# MSPM0G321X register map
Vendor: Texas Instruments; File version: Revised: 2025-10-06 10:58:04
CPU: CM0 r0p1, little endian, MPU, no FPU, 3 interrupt priority bits
Registers are 32-bit, read-write, reset 0x0 unless marked. A register's access mark holds for its fields unless they carry their own. Offsets are from the block's base; [hi:lo] are bit positions; lines under a group give offsets from that group; {n}, {i} and the like mark numbered series; 'fields as' and 'values as' point back to an identical list.

## TIMB0 — PERIPHERALREGION
Base 0x400B8000
0x400 TIMB0_FSUB_0 — Subscriber Configuration Register.
  [3:0] CHANID — 0 = disconnected. 1-15 = connected to channelID = CHANID.
    0=UNCONNECTED (A value of 0 specifies that the event is not connected)
0x444 TIMB0_FPUB_0 — Publisher Port 0
  fields as TIMB0_FSUB_0
{0x800+0x18*i} TIMB0_GPRCM[{i}] (i=0..0) group
  0x00 TIMB0_PWREN — Power enable
    [0] ENABLE — Enable the power
      0=DISABLE (Disable Power); 1=ENABLE (Enable Power)
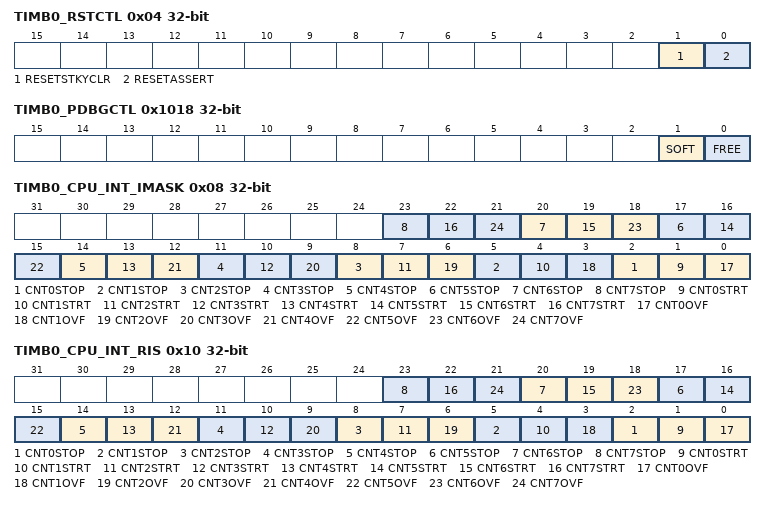
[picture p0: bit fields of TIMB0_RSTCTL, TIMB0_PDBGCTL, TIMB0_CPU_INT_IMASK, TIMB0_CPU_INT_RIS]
  0x04 TIMB0_RSTCTL wo — Reset Control
    [1] RESETSTKYCLR — Clear the RESETSTKY bit in the STAT register
      0=NOP (Writing 0 has no effect); 1=CLR (Clear reset sticky bit)
    [0] RESETASSERT — Assert reset to the peripheral
      0=NOP (Writing 0 has no effect); 1=ASSERT (Assert reset)
  0x14 TIMB0_STAT ro — Status Register
    [16] RESETSTKY — This bit indicates, if the peripheral was reset, since this bit was cleared by RESETSTKYCLR in the RSTCTL register
      0=NORES (The peripheral has not been reset since this bit was last cleared by RESETSTKYCLR in the RSTCTL register); 1=RESET (The peripheral was reset since the last bit clear)
0x1018 TIMB0_PDBGCTL — Peripheral Debug Control
  [1] SOFT — Soft halt boundary control. This function is only available, if [FREE] is set to 'STOP'
    0=IMMEDIATE (The peripheral will halt immediately, even if the resultant state will result in corruption if the system is restarted); 1=DELAYED (The peripheral blocks the debug freeze until it has reached a boundary where it can resume without corruption)
  [0] FREE — Free run control
    0=STOP (The peripheral freezes functionality while the Core Halted input is asserted and resumes when it is deasserted.); 1=RUN (The peripheral ignores the state of the Core Halted input)
{0x1020+0x2C*i} TIMB0_CPU_INT[{i}] (i=0..0) group
  0x00 TIMB0_CPU_INT_IIDX ro — Interrupt index
    [9:0] STAT — Interrupt index status
      0=NO_INTR (No bit is set means there is no pending interrupt request); 1=CNT0OVF (Counter0 period match interrupt); 2=CNT0STRT (Counter 0 start); 3=CNT0STOP (Counter0 stop); 4=CNT1OVF (Counter1 period match interrupt); 5=CNT1STRT (Counter 1 start); 6=CNT1STOP (Counter1 stop); 7=CNT2OVF (Counter2 period match interrupt); 8=CNT2STRT (Counter 2 start); 9=CNT2STOP (Counter2 stop); 10=CNT3OVF (Counter3 period match interrupt); 11=CNT3STRT (Counter 3 start); 12=CNT3STOP (Counter3 stop); 13=CNT4OVF (Counter4 period match interrupt); 14=CNT4STRT (Counter 4 start); 15=CNT4STOP (Counter4 stop); 16=CNT5OVF (Counter5 period match interrupt); 17=CNT5STRT (Counter 5 start); 18=CNT5STOP (Counter5 stop); 19=CNT6OVF (Counter6 period match interrupt); 20=CNT6STRT (Counter 6 start); 21=CNT6STOP (Counter6 stop); 22=CNT7OVF (Counter7 period match interrupt); 23=CNT7STRT (Counter 7 start); 24=CNT7STOP (Counter7 stop)
  0x08 TIMB0_CPU_INT_IMASK — Interrupt Mask. If a bit is set, then corresponding interrupt is un-masked. Un-masking the interrupt causes the raw interrupt to be visible in IIDX, as well as MIS.
    [all] fields
      0=CLR (Interrupt is not pending.); 1=SET (Interrupt is pending.)
    [3n+2] CNT{n}STOP (n=0..7) — CNT{n}STOP Interrupt enable bit
    [3n+1] CNT{n}STRT (n=0..7) — CNT{n}STRT Interrupt enable bit
    [3n] CNT{n}OVF (n=0..7) — CNT{n}OVF Interrupt enable bit
  0x10 TIMB0_CPU_INT_RIS ro — Raw interrupt status. Reflects all pending interrupts, regardless of masking. The RIS register allows the user to implement a poll scheme. A flag set in this register can be cleared by writing 1 to the ICLR register bit even if the corresponding IMASK bit is not enabled.
    [all] fields
      values as the fields of TIMB0_CPU_INT[0].TIMB0_CPU_INT_IMASK
    [3n+2] CNT{n}STOP (n=0..7) — Counter {n} stop event flag
    [3n+1] CNT{n}STRT (n=0..7) — Counter {n} start event flag
    [3n] CNT{n}OVF (n=0..7) — Counter {n} Period match flag
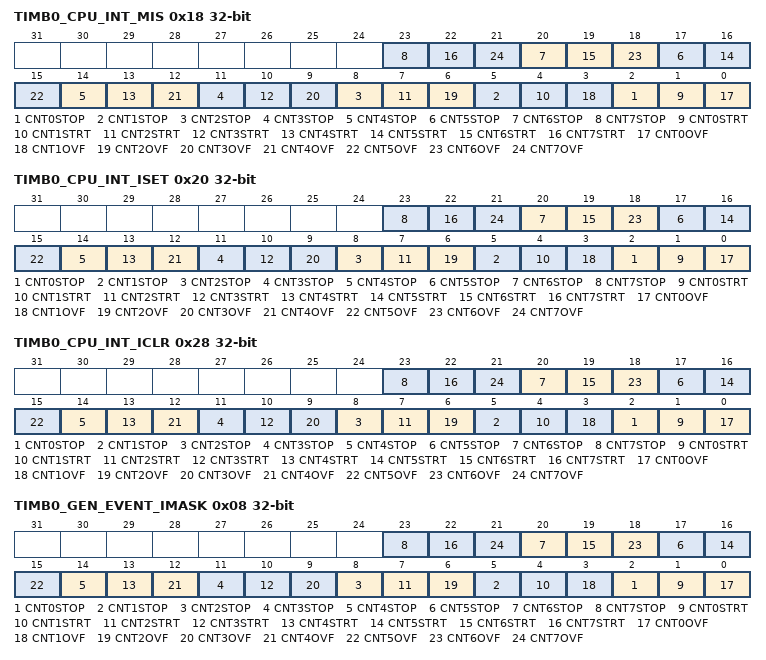
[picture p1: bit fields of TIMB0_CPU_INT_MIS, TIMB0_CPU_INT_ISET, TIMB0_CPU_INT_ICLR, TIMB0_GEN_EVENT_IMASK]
  0x18 TIMB0_CPU_INT_MIS ro — Masked interrupt status. This is an AND of the IMASK and RIS registers.
    [all] fields
      values as the fields of TIMB0_CPU_INT[0].TIMB0_CPU_INT_IMASK
    [3n+2] CNT{n}STOP (n=0..7) — Counter {n} stop event flag.
    [3n+1] CNT{n}STRT (n=0..7) — Counter {n} start event flag.
    [3n] CNT{n}OVF (n=0..7) — Counter {n} period match flag.
  0x20 TIMB0_CPU_INT_ISET wo — Interrupt set. Allows interrupts to be set by software (useful in diagnostics and safety checks). Writing a 1 to a bit in ISET will set the event and therefore the related RIS bit also gets set. If the interrupt is enabled through the mask, then the corresponding MIS bit is also set.
    [all] fields
      0=NO_EFFECT (Interrupt is not pending.); 1=SET (Interrupt is pending.)
    [3n+2] CNT{n}STOP (n=0..7) — Set Counter {n} stop event flag
    [3n+1] CNT{n}STRT (n=0..7) — Set Counter {n} start event flag
    [3n] CNT{n}OVF (n=0..7) — Set Counter {n} period match flag
  0x28 TIMB0_CPU_INT_ICLR wo — Interrupt clear. Write a 1 to clear corresponding Interrupt.
    [all] fields
      0=NO_EFFECT (Interrupt is not pending.); 1=CLR (Interrupt is pending.)
    [3n+2] CNT{n}STOP (n=0..7) — Clear Counter {n} stop event flag.
    [3n+1] CNT{n}STRT (n=0..7) — Clear Counter {n} start event flag.
    [3n] CNT{n}OVF (n=0..7) — Clear Counter {n} period match flag.
{0x1050+0x2C*i} TIMB0_GEN_EVENT[{i}] (i=0..0) group
  0x00 TIMB0_GEN_EVENT_IIDX ro — Interrupt index
    fields as TIMB0_CPU_INT[0].TIMB0_CPU_INT_IIDX
  0x08 TIMB0_GEN_EVENT_IMASK — Interrupt Mask. If a bit is set, then corresponding interrupt is un-masked. Un-masking the interrupt causes the raw interrupt to be visible in IIDX, as well as MIS.
    fields as TIMB0_CPU_INT[0].TIMB0_CPU_INT_IMASK
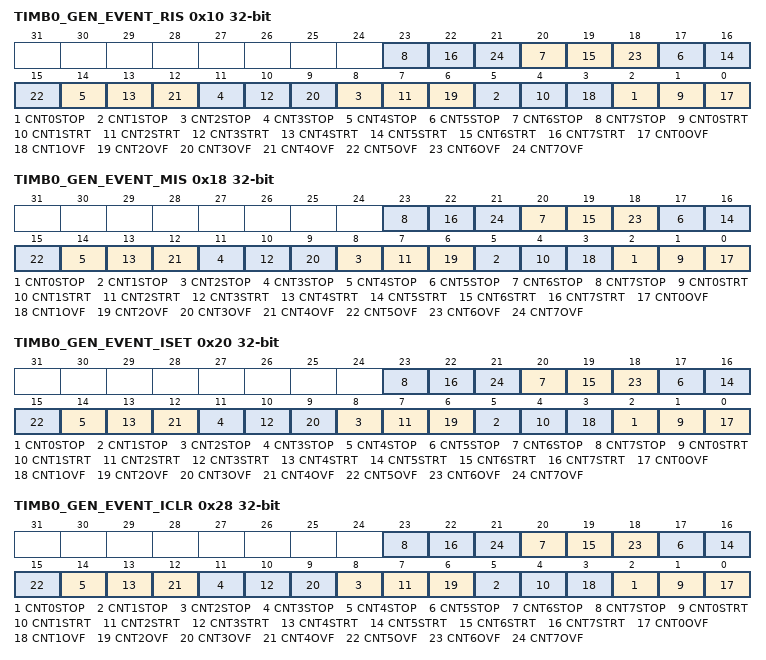
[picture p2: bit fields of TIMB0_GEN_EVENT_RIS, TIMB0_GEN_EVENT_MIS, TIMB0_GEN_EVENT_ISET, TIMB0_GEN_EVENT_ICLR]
  0x10 TIMB0_GEN_EVENT_RIS ro — Raw interrupt status. Reflects all pending interrupts, regardless of masking. The RIS register allows the user to implement a poll scheme. A flag set in this register can be cleared by writing 1 to the ICLR register bit even if the corresponding IMASK bit is not enabled.
    fields as TIMB0_CPU_INT[0].TIMB0_CPU_INT_RIS
  0x18 TIMB0_GEN_EVENT_MIS ro — Masked interrupt status. This is an AND of the IMASK and RIS registers.
    fields as TIMB0_CPU_INT[0].TIMB0_CPU_INT_MIS
  0x20 TIMB0_GEN_EVENT_ISET wo — Interrupt set. Allows interrupts to be set by software (useful in diagnostics and safety checks). Writing a 1 to a bit in ISET will set the event and therefore the related RIS bit also gets set. If the interrupt is enabled through the mask, then the corresponding MIS bit is also set.
    fields as TIMB0_CPU_INT[0].TIMB0_CPU_INT_ISET
  0x28 TIMB0_GEN_EVENT_ICLR wo — Interrupt clear. Write a 1 to clear corresponding Interrupt.
    fields as TIMB0_CPU_INT[0].TIMB0_CPU_INT_ICLR
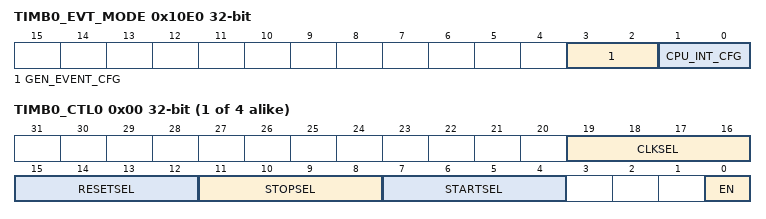
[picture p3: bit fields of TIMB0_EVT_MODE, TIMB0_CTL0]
0x10E0 TIMB0_EVT_MODE ro — Event Mode
  [3:2] GEN_EVENT_CFG — Event line mode select for event corresponding to CPU_INT
    0=DISABLE (The interrupt or event line is disabled.); 1=SOFTWARE (The interrupt or event line is in software mode. Software must clear the RIS.); 2=HARDWARE (The interrupt or event line is in hardware mode. The hardware (another module) clears automatically the associated RIS flag.)
  [1:0] CPU_INT_CFG — Event line mode select for event corresponding to CPU_INT
    values as GEN_EVENT_CFG
{0x1100+0xC*i} TIMB0_CTRREGS[{i}] (i=0..3) group
  0x00 TIMB0_CTL0 — CTL0 register
    [19:16] CLKSEL — Clock sources
    [15:12] RESETSEL — Selects the source used to reset the counter.
    [11:8] STOPSEL — Selects the source used to stop the counter.
    [7:4] STARTSEL — Selects the source used to start the counter.
    [0] EN — Counter Enable
  0x04 TIMB0_LD — Counter period register.
    [15:0] VAL — Period value
  0x08 TIMB0_CNT — Counter register.
    [15:0] VALUE — Counter Value

## TIMB1 — PERIPHERALREGION
Base 0x400BA000
Registers as TIMB0 (with TIMB0 read as TIMB1).
